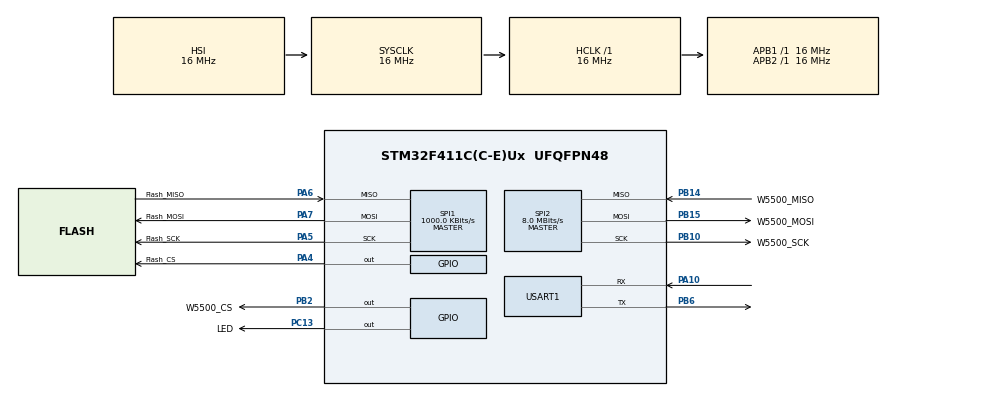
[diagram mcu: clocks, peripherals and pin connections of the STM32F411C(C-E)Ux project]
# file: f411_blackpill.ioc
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FATFS._MAX_SS=4096
FATFS._USE_LFN=1
Mcu.Family=STM32F4
Mcu.Name=STM32F411C(C-E)Ux
Mcu.Package=UFQFPN48
NVIC.PriorityGroup=NVIC_PRIORITYGROUP_4
PA10.Mode=Asynchronous
PA10.Signal=USART1_RX
PA13.Mode=Serial_Wire
PA13.Signal=SYS_JTMS-SWDIO
PA14.Mode=Serial_Wire
PA14.Signal=SYS_JTCK-SWCLK
PA4.GPIO_Label=Flash_CS
PA4.Signal=GPIO_Output
PA5.GPIO_Label=Flash_SCK
PA5.Mode=Full_Duplex_Master
PA5.Signal=SPI1_SCK
PA6.GPIO_Label=Flash_MISO
PA6.Mode=Full_Duplex_Master
PA6.Signal=SPI1_MISO
PA7.GPIO_Label=Flash_MOSI
PA7.Mode=Full_Duplex_Master
PA7.Signal=SPI1_MOSI
PB10.GPIO_Label=W5500_SCK
PB10.Mode=Full_Duplex_Master
PB10.Signal=SPI2_SCK
PB14.GPIO_Label=W5500_MISO
PB14.Mode=Full_Duplex_Master
PB14.Signal=SPI2_MISO
PB15.GPIO_Label=W5500_MOSI
PB15.Mode=Full_Duplex_Master
PB15.Signal=SPI2_MOSI
PB2.GPIO_Label=W5500_CS
PB2.Signal=GPIO_Output
PB6.Mode=Asynchronous
PB6.Signal=USART1_TX
PC13-ANTI_TAMP.GPIO_Label=LED
PC13-ANTI_TAMP.Signal=GPIO_Output
PH0\ -\ OSC_IN.Mode=HSE-External-Clock-Source
PH0\ -\ OSC_IN.Signal=RCC_OSC_IN
PH1\ -\ OSC_OUT.Mode=HSE-External-Clock-Source
PH1\ -\ OSC_OUT.Signal=RCC_OSC_OUT
ProjectManager.HeapSize=0x200
ProjectManager.StackSize=0x400
ProjectManager.TargetToolchain=STM32CubeIDE
RCC.48MHZClocksFreq_Value=48000000
RCC.AHBFreq_Value=16000000
RCC.APB1Freq_Value=16000000
RCC.APB1TimFreq_Value=16000000
RCC.APB2Freq_Value=16000000
RCC.APB2TimFreq_Value=16000000
RCC.CortexFreq_Value=16000000
RCC.HCLKFreq_Value=16000000
RCC.HSE_VALUE=25000000
RCC.HSI_VALUE=16000000
RCC.LSE_VALUE=32768
RCC.SYSCLKFreq_VALUE=16000000
RCC.VCOOutputFreq_Value=192000000
SPI1.BaudRatePrescaler=SPI_BAUDRATEPRESCALER_16
SPI1.CRCCalculation=SPI_CRCCALCULATION_DISABLE
SPI1.CalculateBaudRate=1000.0 KBits/s
SPI1.Direction=SPI_DIRECTION_2LINES
SPI1.Mode=SPI_MODE_MASTER
SPI1.VirtualType=VM_MASTER
SPI2.CalculateBaudRate=8.0 MBits/s
SPI2.Direction=SPI_DIRECTION_2LINES
SPI2.Mode=SPI_MODE_MASTER
SPI2.VirtualType=VM_MASTER
USART1.VirtualMode=VM_ASYNC
VP_FATFS_VS_Generic.Mode=User_defined
board=custom

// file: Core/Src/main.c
/* USER CODE BEGIN Header */
/**
  ******************************************************************************
  * @file           : main.c
  * @brief          : Main program body
  ******************************************************************************
  * @attention
  *
  * Copyright (c) 2024 STMicroelectronics.
  * All rights reserved.
  *
  * This software is licensed under terms that can be found in the LICENSE file
  * in the root directory of this software component.
  * If no LICENSE file comes with this software, it is provided AS-IS.
  *
  ******************************************************************************
  */
/* USER CODE END Header */
#include "main.h"
#include "fatfs.h"

/* USER CODE BEGIN Includes */
#include <FXRTOS.h>
#include <stdbool.h>
#include <stdio.h>
/* USER CODE END Includes */

SPI_HandleTypeDef hspi1;
SPI_HandleTypeDef hspi2;

UART_HandleTypeDef huart1;

void SystemClock_Config(void);
static void MX_GPIO_Init(void);
static void MX_SPI1_Init(void);
static void MX_USART1_UART_Init(void);
static void MX_SPI2_Init(void);

int main(void)
{

  /* MCU Configuration--------------------------------------------------------*/

  /* Reset of all peripherals, Initializes the Flash interface and the Systick. */
  HAL_Init();

  /* USER CODE BEGIN Init */
  NVIC_SetPriority(PendSV_IRQn, 0xFF);
  NVIC_SetPriority(SysTick_IRQn, 0xFF);
  /* USER CODE END Init */

  /* Configure the system clock */
  SystemClock_Config();

  /* USER CODE BEGIN SysInit */
  fx_kernel_entry();
}
  void FX_Init(){
  /* USER CODE END SysInit */

  /* Initialize all configured peripherals */
  MX_GPIO_Init();
  MX_SPI1_Init();
  MX_USART1_UART_Init();
  MX_SPI2_Init();
  MX_FATFS_Init();

  /* Infinite loop */
  /* USER CODE BEGIN WHILE */
	    //while (1)
	     //{
    /* USER CODE END WHILE */

    /* USER CODE BEGIN 3 */
	     //}
  /* USER CODE END 3 */
}

void SystemClock_Config(void)
{
  RCC_OscInitTypeDef RCC_OscInitStruct = {0};
  RCC_ClkInitTypeDef RCC_ClkInitStruct = {0};

  /** Configure the main internal regulator output voltage
  */
  __HAL_RCC_PWR_CLK_ENABLE();
  __HAL_PWR_VOLTAGESCALING_CONFIG(PWR_REGULATOR_VOLTAGE_SCALE1);

  /** Initializes the RCC Oscillators according to the specified parameters
  * in the RCC_OscInitTypeDef structure.
  */
  RCC_OscInitStruct.OscillatorType = RCC_OSCILLATORTYPE_HSI;
  RCC_OscInitStruct.HSIState = RCC_HSI_ON;
  RCC_OscInitStruct.HSICalibrationValue = RCC_HSICALIBRATION_DEFAULT;
  RCC_OscInitStruct.PLL.PLLState = RCC_PLL_NONE;
  if (HAL_RCC_OscConfig(&RCC_OscInitStruct) != HAL_OK)
  {
    Error_Handler();
  }

  /** Initializes the CPU, AHB and APB buses clocks
  */
  RCC_ClkInitStruct.ClockType = RCC_CLOCKTYPE_HCLK|RCC_CLOCKTYPE_SYSCLK
                              |RCC_CLOCKTYPE_PCLK1|RCC_CLOCKTYPE_PCLK2;
  RCC_ClkInitStruct.SYSCLKSource = RCC_SYSCLKSOURCE_HSI;
  RCC_ClkInitStruct.AHBCLKDivider = RCC_SYSCLK_DIV1;
  RCC_ClkInitStruct.APB1CLKDivider = RCC_HCLK_DIV1;
  RCC_ClkInitStruct.APB2CLKDivider = RCC_HCLK_DIV1;

  if (HAL_RCC_ClockConfig(&RCC_ClkInitStruct, FLASH_LATENCY_0) != HAL_OK)
  {
    Error_Handler();
  }
}

static void MX_SPI1_Init(void)
{

  /* SPI1 parameter configuration*/
  hspi1.Instance = SPI1;
  hspi1.Init.Mode = SPI_MODE_MASTER;
  hspi1.Init.Direction = SPI_DIRECTION_2LINES;
  hspi1.Init.DataSize = SPI_DATASIZE_8BIT;
  hspi1.Init.CLKPolarity = SPI_POLARITY_LOW;
  hspi1.Init.CLKPhase = SPI_PHASE_1EDGE;
  hspi1.Init.NSS = SPI_NSS_SOFT;
  hspi1.Init.BaudRatePrescaler = SPI_BAUDRATEPRESCALER_16;
  hspi1.Init.FirstBit = SPI_FIRSTBIT_MSB;
  hspi1.Init.TIMode = SPI_TIMODE_DISABLE;
  hspi1.Init.CRCCalculation = SPI_CRCCALCULATION_DISABLE;
  hspi1.Init.CRCPolynomial = 10;
  if (HAL_SPI_Init(&hspi1) != HAL_OK)
  {
    Error_Handler();
  }

}

static void MX_SPI2_Init(void)
{

  /* SPI2 parameter configuration*/
  hspi2.Instance = SPI2;
  hspi2.Init.Mode = SPI_MODE_MASTER;
  hspi2.Init.Direction = SPI_DIRECTION_2LINES;
  hspi2.Init.DataSize = SPI_DATASIZE_8BIT;
  hspi2.Init.CLKPolarity = SPI_POLARITY_LOW;
  hspi2.Init.CLKPhase = SPI_PHASE_1EDGE;
  hspi2.Init.NSS = SPI_NSS_SOFT;
  hspi2.Init.BaudRatePrescaler = SPI_BAUDRATEPRESCALER_2;
  hspi2.Init.FirstBit = SPI_FIRSTBIT_MSB;
  hspi2.Init.TIMode = SPI_TIMODE_DISABLE;
  hspi2.Init.CRCCalculation = SPI_CRCCALCULATION_DISABLE;
  hspi2.Init.CRCPolynomial = 10;
  if (HAL_SPI_Init(&hspi2) != HAL_OK)
  {
    Error_Handler();
  }

}

static void MX_USART1_UART_Init(void)
{

  huart1.Instance = USART1;
  huart1.Init.BaudRate = 115200;
  huart1.Init.WordLength = UART_WORDLENGTH_8B;
  huart1.Init.StopBits = UART_STOPBITS_1;
  huart1.Init.Parity = UART_PARITY_NONE;
  huart1.Init.Mode = UART_MODE_TX_RX;
  huart1.Init.HwFlowCtl = UART_HWCONTROL_NONE;
  huart1.Init.OverSampling = UART_OVERSAMPLING_16;
  if (HAL_UART_Init(&huart1) != HAL_OK)
  {
    Error_Handler();
  }

}

static void MX_GPIO_Init(void)
{
  GPIO_InitTypeDef GPIO_InitStruct = {0};

  /* GPIO Ports Clock Enable */
  __HAL_RCC_GPIOC_CLK_ENABLE();
  __HAL_RCC_GPIOH_CLK_ENABLE();
  __HAL_RCC_GPIOA_CLK_ENABLE();
  __HAL_RCC_GPIOB_CLK_ENABLE();

  /*Configure GPIO pin Output Level */
  HAL_GPIO_WritePin(LED_GPIO_Port, LED_Pin, GPIO_PIN_RESET);

  /*Configure GPIO pin Output Level */
  HAL_GPIO_WritePin(Flash_CS_GPIO_Port, Flash_CS_Pin, GPIO_PIN_RESET);

  /*Configure GPIO pin Output Level */
  HAL_GPIO_WritePin(W5500_CS_GPIO_Port, W5500_CS_Pin, GPIO_PIN_RESET);

  /*Configure GPIO pin : LED_Pin */
  GPIO_InitStruct.Pin = LED_Pin;
  GPIO_InitStruct.Mode = GPIO_MODE_OUTPUT_PP;
  GPIO_InitStruct.Pull = GPIO_NOPULL;
  GPIO_InitStruct.Speed = GPIO_SPEED_FREQ_LOW;
  HAL_GPIO_Init(LED_GPIO_Port, &GPIO_InitStruct);

  /*Configure GPIO pin : Flash_CS_Pin */
  GPIO_InitStruct.Pin = Flash_CS_Pin;
  GPIO_InitStruct.Mode = GPIO_MODE_OUTPUT_PP;
  GPIO_InitStruct.Pull = GPIO_NOPULL;
  GPIO_InitStruct.Speed = GPIO_SPEED_FREQ_LOW;
  HAL_GPIO_Init(Flash_CS_GPIO_Port, &GPIO_InitStruct);

  /*Configure GPIO pin : W5500_CS_Pin */
  GPIO_InitStruct.Pin = W5500_CS_Pin;
  GPIO_InitStruct.Mode = GPIO_MODE_OUTPUT_PP;
  GPIO_InitStruct.Pull = GPIO_NOPULL;
  GPIO_InitStruct.Speed = GPIO_SPEED_FREQ_LOW;
  HAL_GPIO_Init(W5500_CS_GPIO_Port, &GPIO_InitStruct);

}

/* USER CODE BEGIN 4 */
void fx_intr_handler(void)
{

}

//int _io_putchar(int ch)
//{
//	HAL_UART_Transmit(&huart2, (uint8_t *)&ch, 1, HAL_MAX_DELAY);
//	return ch;
//}

int _write(int file, char *ptr, int len) {
	HAL_UART_Transmit(&huart1, (uint8_t *)ptr, len, HAL_MAX_DELAY);
	return len;
}
/* USER CODE END 4 */

void Error_Handler(void)
{
  __disable_irq();
  while (1)
  {
  }
}
